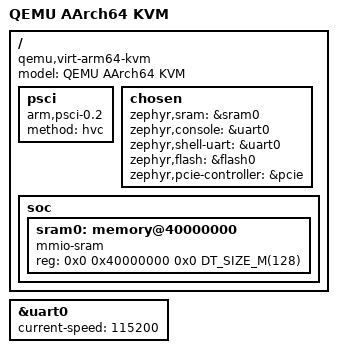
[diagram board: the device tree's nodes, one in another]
/*
 * Copyright (c) 2019 Carlo Caione <ccaione@baylibre.com>
 * Copyright (c) 2022 Huawei France Technologies SASU
 *
 * SPDX-License-Identifier: Apache-2.0
 *
 */

/dts-v1/;
#include <arm64/qemu/qemu-virt-arm64.dtsi>

/ {
	model = "QEMU AArch64 KVM";
	compatible = "qemu,virt-arm64-kvm";

	psci {
		compatible = "arm,psci-0.2";
		method = "hvc";
	};

	chosen {
		zephyr,sram = &sram0;
		zephyr,console = &uart0;
		zephyr,shell-uart = &uart0;
		zephyr,flash = &flash0;
		zephyr,pcie-controller = &pcie;
	};

	soc {
		sram0: memory@40000000 {
			compatible = "mmio-sram";
			reg = <0x0 0x40000000 0x0 DT_SIZE_M(128)>;
		};

	};
};

&uart0 {
	status = "okay";
	current-speed = <115200>;
};
